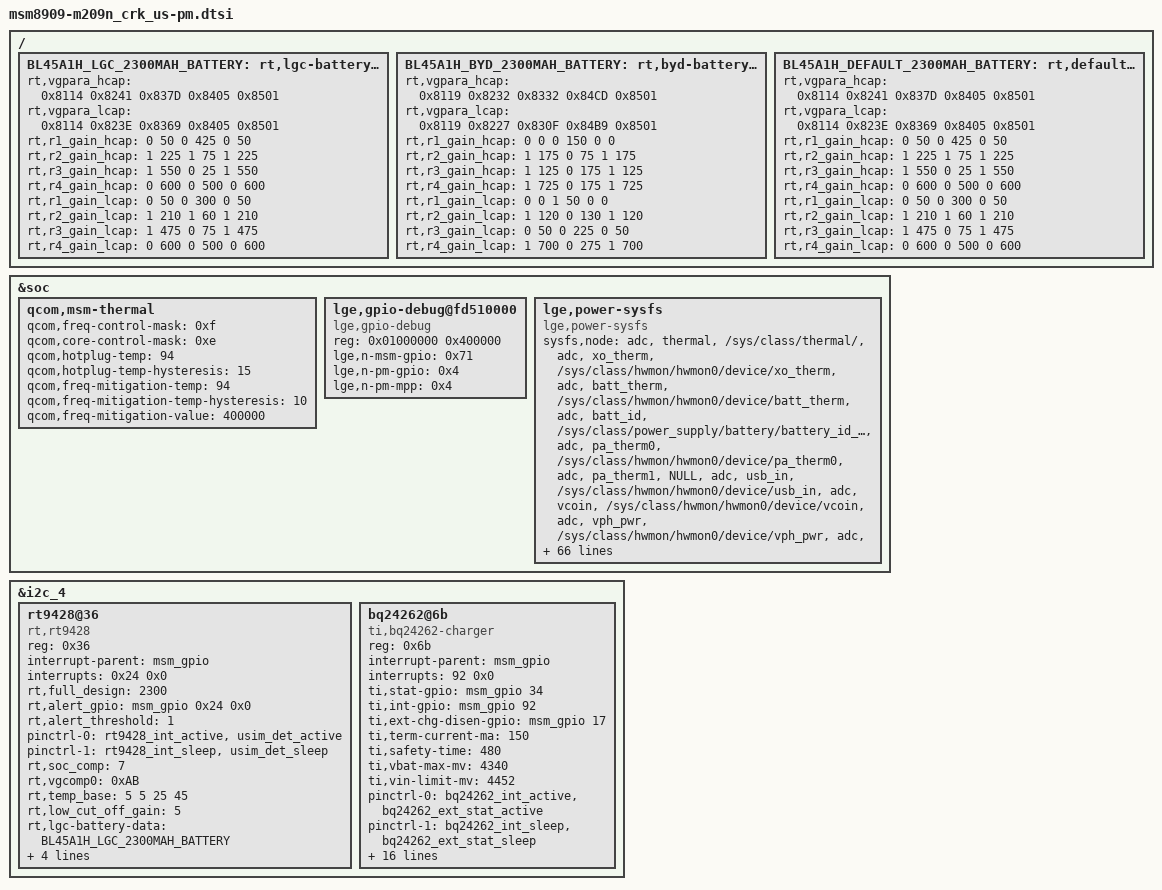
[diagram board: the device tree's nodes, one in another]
/* Copyright (c) 2014, The Linux Foundation. All rights reserved.
 *
 * This program is free software; you can redistribute it and/or modify
 * it under the terms of the GNU General Public License version 2 and
 * only version 2 as published by the Free Software Foundation.
 *
 * This program is distributed in the hope that it will be useful,
 * but WITHOUT ANY WARRANTY; without even the implied warranty of
 * MERCHANTABILITY or FITNESS FOR A PARTICULAR PURPOSE.  See the
 * GNU General Public License for more details.
 */

&soc {
	qcom,msm-thermal {
		qcom,freq-control-mask = <0xf>;
		qcom,core-control-mask = <0xe>;
		qcom,hotplug-temp = <94>;
		qcom,hotplug-temp-hysteresis = <15>;
		qcom,freq-mitigation-temp = <94>;
		qcom,freq-mitigation-temp-hysteresis = <10>;
		qcom,freq-mitigation-value = <400000>;
		};
};

/ {
	BL45A1H_LGC_2300MAH_BATTERY: rt,lgc-battery-data {
		rt,vgpara_hcap = <0x8114 0x8241 0x837D 0x8405 0x8501>;
		rt,vgpara_lcap = <0x8114 0x823E 0x8369 0x8405 0x8501>;
		rt,r1_gain_hcap = < 0 50 0 425 0 50>;
		rt,r2_gain_hcap = < 1 225 1 75 1 225>;
		rt,r3_gain_hcap = < 1 550 0 25 1 550>;
		rt,r4_gain_hcap = < 0 600 0 500 0 600>;
		rt,r1_gain_lcap = < 0 50 0 300 0 50>;
		rt,r2_gain_lcap = < 1 210 1 60 1 210>;
		rt,r3_gain_lcap = < 1 475 0 75 1 475>;
		rt,r4_gain_lcap = < 0 600 0 500 0 600>;
	};

	BL45A1H_BYD_2300MAH_BATTERY: rt,byd-battery-data {
		rt,vgpara_hcap = <0x8119 0x8232 0x8332 0x84CD 0x8501>;
		rt,vgpara_lcap = <0x8119 0x8227 0x830F 0x84B9 0x8501>;
		rt,r1_gain_hcap = < 0 0 0 150 0 0>;
		rt,r2_gain_hcap = < 1 175 0 75 1 175>;
		rt,r3_gain_hcap = < 1 125 0 175 1 125>;
		rt,r4_gain_hcap = < 1 725 0 175 1 725>;
		rt,r1_gain_lcap = < 0 0 1 50 0 0>;
		rt,r2_gain_lcap = < 1 120 0 130 1 120>;
		rt,r3_gain_lcap = < 0 50 0 225 0 50>;
		rt,r4_gain_lcap = < 1 700 0 275 1 700>;
	};

	BL45A1H_DEFAULT_2300MAH_BATTERY: rt,default-battery-data {
		rt,vgpara_hcap = <0x8114 0x8241 0x837D 0x8405 0x8501>;
		rt,vgpara_lcap = <0x8114 0x823E 0x8369 0x8405 0x8501>;
		rt,r1_gain_hcap = < 0 50 0 425 0 50>;
		rt,r2_gain_hcap = < 1 225 1 75 1 225>;
		rt,r3_gain_hcap = < 1 550 0 25 1 550>;
		rt,r4_gain_hcap = < 0 600 0 500 0 600>;
		rt,r1_gain_lcap = < 0 50 0 300 0 50>;
		rt,r2_gain_lcap = < 1 210 1 60 1 210>;
		rt,r3_gain_lcap = < 1 475 0 75 1 475>;
		rt,r4_gain_lcap = < 0 600 0 500 0 600>;
	};
};

/* M2 ATnT using i2c_4(BLSP4) from rev.A */
&i2c_4 {
	rt9428@36 {
		compatible = "rt,rt9428";
		status = "ok";
		reg = <0x36>;
		interrupt-parent = <&msm_gpio>;
		interrupts = <0x24 0x0>;
		rt,full_design= <2300>;
		rt,alert_gpio = <&msm_gpio 0x24 0x0>;
		rt,alert_threshold = <1>;
		/* Pins config setting */
		pinctrl-names = "default", "sleep";
		pinctrl-0 = <&rt9428_int_active &usim_det_active>;
		pinctrl-1 = <&rt9428_int_sleep &usim_det_sleep>;
		rt,soc_comp = <7>;
		rt,vgcomp0 = <0xAB>;
		rt,temp_base = <5 5 25 45>;
		rt,low_cut_off_gain = <5>;
		rt,lgc-battery-data = <&BL45A1H_LGC_2300MAH_BATTERY>;
		rt,byd-battery-data = <&BL45A1H_BYD_2300MAH_BATTERY>;
		rt,default-battery-data = <&BL45A1H_DEFAULT_2300MAH_BATTERY>;
	};
	bq24262@6b {
		status = "ok";
		compatible = "ti,bq24262-charger";
		reg = <0x6b>;
		interrupt-parent = <&msm_gpio>;
		interrupts = <92 0x0>;
		ti,stat-gpio = <&msm_gpio 34 0>;
		ti,int-gpio = <&msm_gpio 92 0>;
		ti,ext-chg-disen-gpio = <&msm_gpio 17 0>;
		ti,term-current-ma = <150>;
		ti,safety-time = <480>;
		ti,vbat-max-mv = <4340>;	/* Step unit 20 mV, battery available voltage(x = 4.375) : x-0.025 ~ x ~ x+0.025 */
		ti,vin-limit-mv = <4452>;
		/* Pins config setting */
		pinctrl-names = "default", "sleep";
		pinctrl-0 = <&bq24262_int_active &bq24262_ext_stat_active>;
		pinctrl-1 = <&bq24262_int_sleep &bq24262_ext_stat_sleep>;

		/* Each model is defferently value */
		lge,no-init-cable = <0 0 0>;
		lge,cable-mhl-1k = <5000 500 500>;
		lge,cable-u-28p7k = <5500 800 500>;
		lge,cable-28p7k = <6000 800 500>;
		lge,cable-56k = <200000 1500 1500>;
		lge,cable-100k = <239000 800 500>;
		lge,cable-130k = <340000 1500 1500>;
		lge,cable-180k = <400000 800 500>;
		lge,cable-200k = <410000 800 500>;
		lge,cable-220k = <485000 800 500>;
		lge,cable-270k = <560000 800 500>;
		lge,cable-330k = <735000 800 500>;
		lge,cable-620k = <955000 800 500>;
		lge,cable-910k = <1140000 1500 1500>;
		lge,cable-none = <1900000 800  500>;

		qcom,bq24262-vadc = <&pm8916_vadc>;
	};
};

&soc {
	lge,gpio-debug@fd510000 {
		compatible = "lge,gpio-debug";
		reg = <0x01000000 0x400000>;
		reg-names = "tlmm-base";
		lge,n-msm-gpio = <0x71>;
		lge,n-pm-gpio = <0x4>;
		lge,n-pm-mpp = <0x4>;
	};
};

&soc {
	lge,power-sysfs {
		compatible = "lge,power-sysfs";

		sysfs,node =
			/* group , user_node,  kernel node */
			/* ADC/MPP */
			"adc", "thermal", "/sys/class/thermal/",
			"adc", "xo_therm", "/sys/class/hwmon/hwmon0/device/xo_therm",
			"adc", "batt_therm", "/sys/class/hwmon/hwmon0/device/batt_therm",
			"adc", "batt_id", "/sys/class/power_supply/battery/battery_id_checker",
			"adc", "pa_therm0", "/sys/class/hwmon/hwmon0/device/pa_therm0",
			"adc", "pa_therm1", "NULL",
			"adc", "usb_in", "/sys/class/hwmon/hwmon0/device/usb_in",
			"adc", "vcoin", "/sys/class/hwmon/hwmon0/device/vcoin",
			"adc", "vph_pwr", "/sys/class/hwmon/hwmon0/device/vph_pwr",
			"adc", "usb_id", "/sys/class/hwmon/hwmon0/device/usb_id",
			/* Battery */
			"battery", "capacity", "/sys/class/power_supply/battery/capacity",
			"battery", "health", "/sys/class/power_supply/battery/health",
			"battery", "present", "/sys/class/power_supply/battery/present",
			"battery", "pseudo_batt", "/sys/class/power_supply/battery/pseudo_batt",
			"battery", "status", "/sys/class/power_supply/battery/status",
			"battery", "temp", "/sys/class/power_supply/battery/temp",
			"battery", "valid_batt_id", "/sys/class/power_supply/battery/valid_batt_id",
			"battery", "voltage_now", "/sys/class/power_supply/battery/voltage_now",
			/* Charger */
			"charger", "ac_online", "NULL",
			"charger", "usb_online", "/sys/class/power_supply/usb/online",
			"charger", "present", "/sys/class/power_supply/usb/present",
			"charger", "wlc_online", "NULL",
			"charger", "type", "/sys/class/power_supply/usb/type",
			"charger", "time_out", "NULL",
			"charger", "charging_enabled", "/sys/class/power_supply/battery/charging_enabled",
			"charger", "ibat_current", "/sys/class/power_supply/battery/current_now",
			"charger", "ichg_current", "/sys/class/power_supply/usb/current_max",
			"charger", "iusb_control", "NULL",
			"charger", "thermal_mitigation", "/sys/module/bq24262_charger/parameters/bq24262_thermal_mitigation",
			"charger", "wlc_thermal_mitigation", "NULL",
			"charger", "usb_parallel_chg_status", "NULL",
			"charger", "usb_parallel_charging_enabled", "NULL",
			/* LCD Backlight */
			"lcd", "brightness", "/sys/class/leds/lcd-backlight/brightness",
			"lcd", "max_brightness", "/sys/class/leds/lcd-backlight/max_brightness",
			/* KEY LED */
			"key_led", "red_brightness", "/sys/class/leds/R/brightness",
			"key_led", "green_brightness", "/sys/class/leds/G/brightness",
			"key_led", "blue_brightness", "/sys/class/leds/B/brightness",
			/* CPU */
			"cpu", "cpu_idle_modes", "NULL",
			/* GPU */
			"gpu", "busy", "/sys/class/kgsl/kgsl-3d0/gpubusy",
			/* PLATFORM */
			"platform", "speed_bin", "NULL",
			"platform", "pvs_bin", "NULL",
			"platform", "power_state", "/sys/power/autosleep",
			"platform", "poweron_alarm", "/sys/module/qpnp_rtc/parameters/poweron_alarm",
			"platform", "pcb_rev", "/sys/class/hwmon/hwmon0/device/pcb_rev",
			/* testmode */
			"testmode", "charge", "/sys/class/power_supply/battery/device/at_charge",
			"testmode", "chcomp", "/sys/class/power_supply/battery/device/at_chcomp1",
			"testmode", "chgmodeoff", "/sys/class/power_supply/battery/charging_enabled",
			"testmode", "fuelrst", "/sys/bus/i2c/devices/4-0036/fuelrst",
			"testmode", "rtc_time", "/dev/rtc0",
			"testmode", "pmrst", "NULL",
			"testmode", "battexit", "/sys/class/power_supply/battery/present"
			;
	};
};
